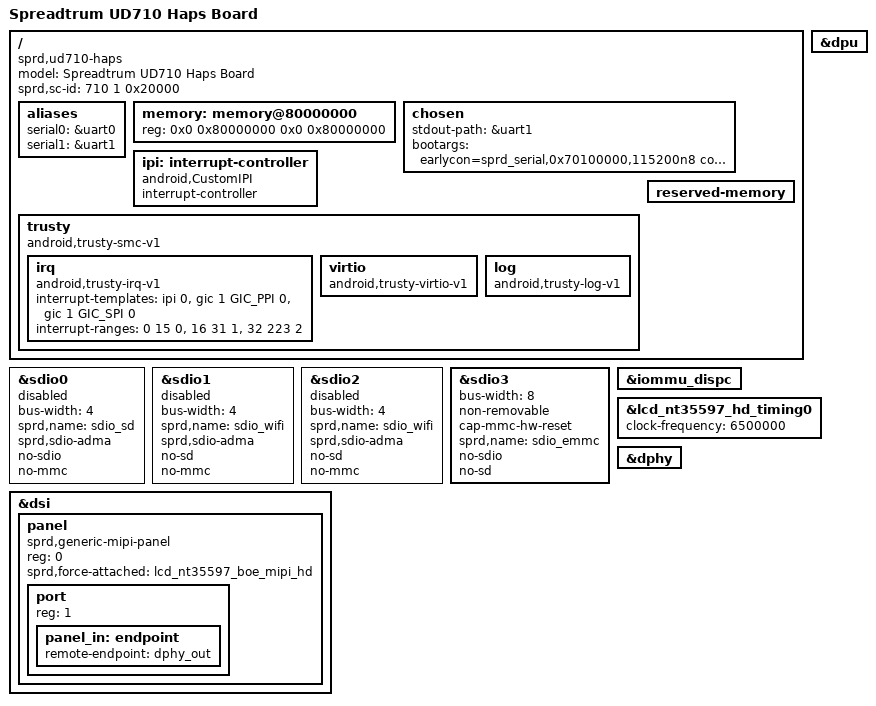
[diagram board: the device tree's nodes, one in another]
/*
 * Spreadtrum Roc1 Haps board DTS file
 *
 * Copyright (C) 2018, Spreadtrum Communications Inc.
 *
 * This file is licensed under a dual GPLv2 or X11 license.
 */
/dts-v1/;

#include "uc710haps.dtsi"
#include "uc710haps-common.dtsi"
#include "lcd/lcd_nt35597_boe_mipi_hd.dtsi"

/ {
	model = "Spreadtrum UD710 Haps Board";

	compatible = "sprd,ud710-haps", "sprd,ud710";

	sprd,sc-id = <710 1 0x20000>;

	aliases {
		serial0 = &uart0;
		serial1 = &uart1;
	};

	memory: memory@80000000 {
		device_type = "memory";
		reg = <0x0 0x80000000 0x0 0x80000000>;
	};

	chosen {
		stdout-path = &uart1;
		bootargs = "earlycon=sprd_serial,0x70100000,115200n8 console=ttyS1,115200n8 loglevel=8 maxcpus=1 init=/init root=/dev/mmcblk0p30 rootfstype=ext4 rw rootwait androidboot.hardware=ud710_haps androidboot.selinux=permissive";
	};

	ipi: interrupt-controller {
		compatible = "android,CustomIPI";
		#interrupt-cells = <1>;
		interrupt-controller;
	};

	trusty {
		compatible = "android,trusty-smc-v1";

		irq {
			compatible = "android,trusty-irq-v1";
			interrupt-templates = <&ipi 0>,
						<&gic 1 GIC_PPI 0>,
						<&gic 1 GIC_SPI 0>;
			interrupt-ranges = < 0  15 0>,
						<16  31 1>,
						<32 223 2>;
		};

		virtio {
			compatible = "android,trusty-virtio-v1";
		};

		log {
			compatible = "android,trusty-log-v1";
		};
	};

	reserved-memory {
		#address-cells = <2>;
		#size-cells = <2>;
		ranges;
	};
};

&sdio0 {
	bus-width = <4>;
	sprd,name = "sdio_sd";
	sprd,sdio-adma;
	no-sdio;
	no-mmc;
	status = "disabled";
};

&sdio1 {
	bus-width = <4>;
	sprd,name = "sdio_wifi";
	sprd,sdio-adma;
	no-sd;
	no-mmc;
	status = "disabled";
};

&sdio2 {
	bus-width = <4>;
	sprd,name = "sdio_wifi";
	sprd,sdio-adma;
	no-sd;
	no-mmc;
	status = "disabled";
};

&sdio3 {
	bus-width = <8>;
	non-removable;
	cap-mmc-hw-reset;
	sprd,name = "sdio_emmc";
	no-sdio;
	no-sd;
	status = "okay";
};

&dpu {
	status = "okay";
};

&iommu_dispc {
	status = "okay";
};

&dsi {
	status = "okay";
	#address-cells = <1>;
	#size-cells = <0>;

	panel {
		compatible = "sprd,generic-mipi-panel";
		#address-cells = <1>;
		#size-cells = <0>;
		reg = <0>;

		sprd,force-attached = "lcd_nt35597_boe_mipi_hd";
		port {
			reg = <1>;
			panel_in: endpoint {
				remote-endpoint = <&dphy_out>;
			};
		};
	};
};

&lcd_nt35597_hd_timing0 {
	clock-frequency = <6500000>;
};

&dphy {
	status = "okay";
};
